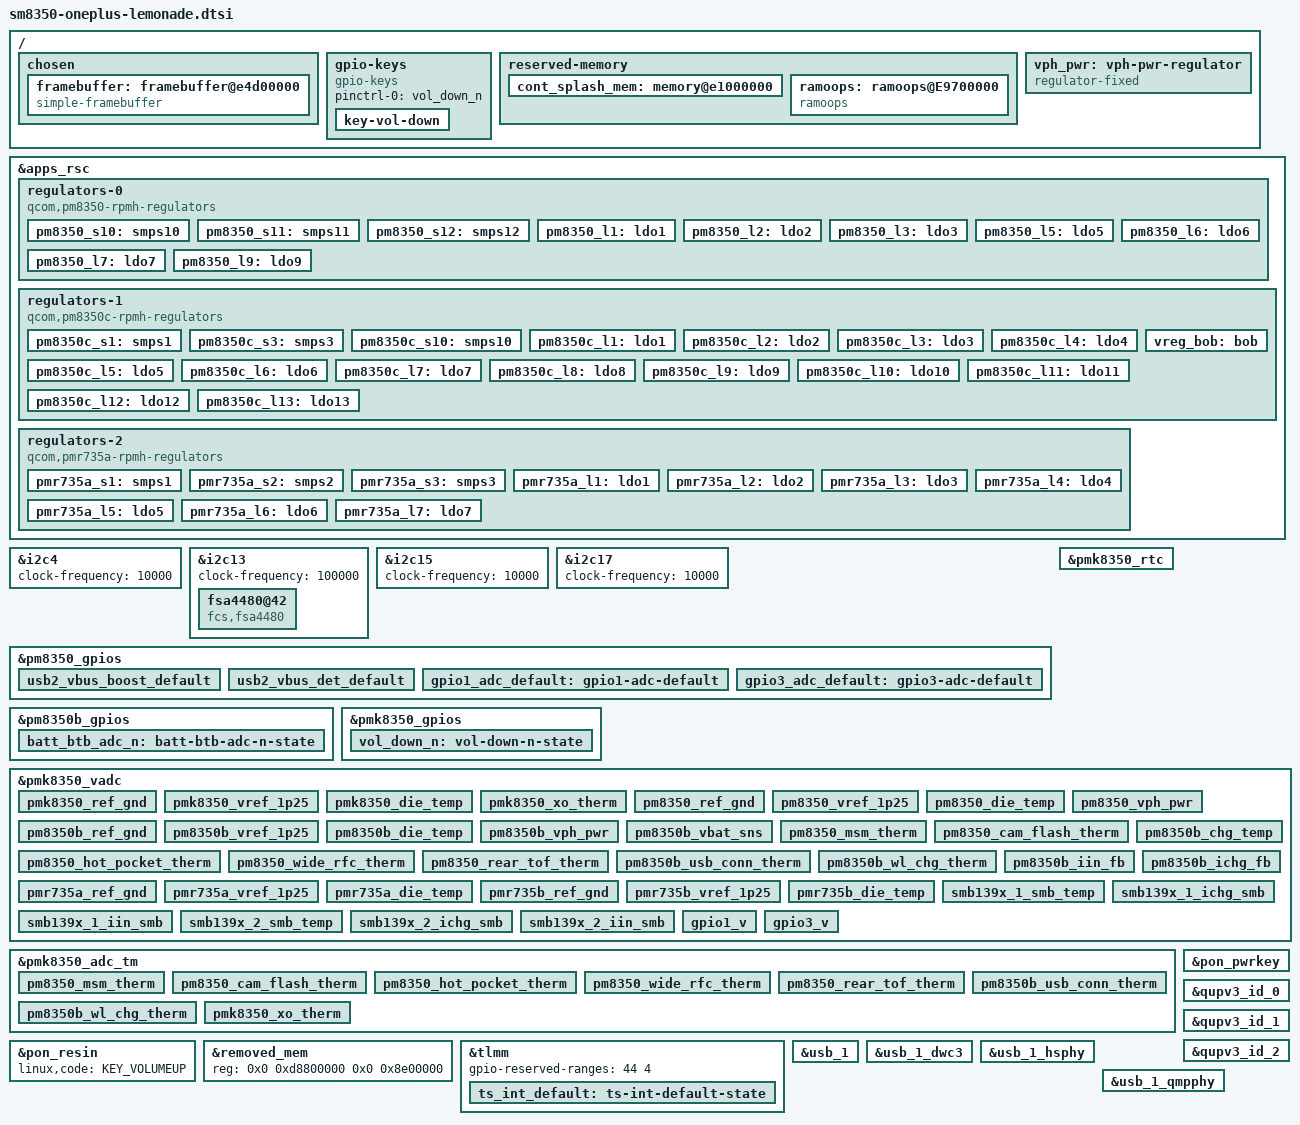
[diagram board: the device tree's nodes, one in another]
// SPDX-License-Identifier: BSD-3-Clause
/*
 *
 * Copyright (c) 2023, Linaro Limited
 */

#include <dt-bindings/iio/qcom,spmi-adc7-pm8350.h>
#include <dt-bindings/iio/qcom,spmi-adc7-pm8350b.h>
#include <dt-bindings/iio/qcom,spmi-adc7-smb139x.h>
#include <dt-bindings/pinctrl/qcom,pmic-gpio.h>
#include <dt-bindings/regulator/qcom,rpmh-regulator.h>
#include "sm8350.dtsi"
#include "pm8350.dtsi"
#include "pm8350b.dtsi"
#include "pm8350c.dtsi"
#include "pmk8350.dtsi"
#include "pmr735a.dtsi"
#include "pmr735b.dtsi"

/ {
	chassis-type = "handset";
	qcom,msm-id = <415 0x10000>, <456 0x10000>;
	qcom,board-id = <0 0>;
	interrupt-parent = <&intc>;

	chosen {
		#address-cells = <2>;
		#size-cells = <2>;
		ranges;

		framebuffer: framebuffer@e4d00000 {
			compatible = "simple-framebuffer";
			reg = <0 0xE4D00000 0 0x2400000>;
			width = <1080>;
			height = <2412>;
			stride = <(1080 * 4)>;
			format = "a8r8g8b8";
			/*
			 * That's (going to be) a lot of clocks, but it's necessary due
			 * to unused clk cleanup & no panel driver yet
			 */
			clocks = <&gcc GCC_DISP_HF_AXI_CLK>,
				 <&gcc GCC_DISP_SF_AXI_CLK>;
		};
	};

	gpio-keys {
		compatible = "gpio-keys";

		pinctrl-names = "default";
		pinctrl-0 = <&vol_down_n>;

		key-vol-down {
			label = "Volume Down";
			linux,code = <KEY_VOLUMEDOWN>;
			gpios = <&pmk8350_gpios 6 GPIO_ACTIVE_LOW>;
			debounce-interval = <15>;
			linux,can-disable;
			wakeup-source;
		};
	};

	// pmic-glink {
	// 	compatible = "qcom,sm8350-pmic-glink", "qcom,pmic-glink";
	// 	#address-cells = <1>;
	// 	#size-cells = <0>;

	// 	connector@0 {
	// 		compatible = "usb-c-connector";
	// 		reg = <0>;
	// 		power-role = "dual";
	// 		data-role = "dual";

	// 		ports {
	// 			#address-cells = <1>;
	// 			#size-cells = <0>;

	// 			port@0 {
	// 				reg = <0>;

	// 				pmic_glink_hs_in: endpoint {
	// 					remote-endpoint = <&usb_1_dwc3_hs>;
	// 				};
	// 			};

	// 			port@1 {
	// 				reg = <1>;

	// 				pmic_glink_ss_in: endpoint {
	// 					remote-endpoint = <&usb_1_dwc3_ss>;
	// 				};
	// 			};
	// 		};
	// 	};
	// };

	reserved-memory {
		cont_splash_mem: memory@e1000000 {
			reg = <0 0xe4d00000 0 0x02400000>;
			no-map;
		};

		ramoops: ramoops@E9700000 {
			compatible = "ramoops";
			reg = <0 0xE9700000 0 0x05B8000>; //5M + 736k
			record-size =  <0x40000>; //256k
			console-size = <0x40000>; //256k
			ftrace-size =  <0x200000>; //2M
			pmsg-size=     <0x200000>; //2M
			devinfo-size=  <0x08000>;  //32k
			dumpinfo-size=  <0x08000>; //32k
			rsv01info-size=  <0x08000>; //32k
			rsv02info-size=  <0x08000>; //32k
			rsv03info-size=  <0x08000>; //32k
			rsv04info-size=  <0x08000>; //32k
			rsv05info-size=  <0x08000>; //32k
			ecc-size=      <0x0>;
		};
	};

	vph_pwr: vph-pwr-regulator {
		compatible = "regulator-fixed";
		regulator-name = "vph_pwr";
		regulator-min-microvolt = <3700000>;
		regulator-max-microvolt = <3700000>;

		regulator-always-on;
		regulator-boot-on;
	};
};

// &adsp {
// 	status = "okay";
// 	firmware-name = "qcom/sm8350/OnePlus/lemonade/adsp.mbn";
// };

&apps_rsc {
	regulators-0 {
		compatible = "qcom,pm8350-rpmh-regulators";
		qcom,pmic-id = "b";

		vdd-s1-supply = <&vph_pwr>;
		vdd-s2-supply = <&vph_pwr>;
		vdd-s3-supply = <&vph_pwr>;
		vdd-s4-supply = <&vph_pwr>;
		vdd-s5-supply = <&vph_pwr>;
		vdd-s6-supply = <&vph_pwr>;
		vdd-s7-supply = <&vph_pwr>;
		vdd-s8-supply = <&vph_pwr>;
		vdd-s9-supply = <&vph_pwr>;
		vdd-s10-supply = <&vph_pwr>;
		vdd-s11-supply = <&vph_pwr>;
		vdd-s12-supply = <&vph_pwr>;

		vdd-l1-l4-supply = <&pm8350_s11>;
		vdd-l2-l7-supply = <&vreg_bob>;
		vdd-l3-l5-supply = <&vreg_bob>;
		vdd-l6-l9-l10-supply = <&pm8350_s11>;

		/*
		 * ARC regulators:
		 * S5 - mx.lvl
		 * S6 - gfx.lvl
		 * S9 - mxc.lvl
		 */

		pm8350_s10: smps10 {
			regulator-name = "pm8350_s10";
			regulator-min-microvolt = <1800000>;
			regulator-max-microvolt = <1800000>;
			regulator-initial-mode = <RPMH_REGULATOR_MODE_HPM>;
		};

		pm8350_s11: smps11 {
			regulator-name = "pm8350_s11";
			regulator-min-microvolt = <752000>;
			regulator-max-microvolt = <1012000>;
			regulator-initial-mode = <RPMH_REGULATOR_MODE_HPM>;
		};

		pm8350_s12: smps12 {
			regulator-name = "pm8350_s12";
			regulator-min-microvolt = <1224000>;
			regulator-max-microvolt = <1360000>;
			regulator-initial-mode = <RPMH_REGULATOR_MODE_HPM>;
		};

		pm8350_l1: ldo1 {
			regulator-name = "pm8350_l1";
			regulator-min-microvolt = <912000>;
			regulator-max-microvolt = <920000>;
			regulator-initial-mode = <RPMH_REGULATOR_MODE_HPM>;
		};

		pm8350_l2: ldo2 {
			regulator-name = "pm8350_l2";
			regulator-min-microvolt = <3072000>;
			regulator-max-microvolt = <3072000>;
			regulator-initial-mode = <RPMH_REGULATOR_MODE_HPM>;
		};

		pm8350_l3: ldo3 {
			regulator-name = "pm8350_l3";
			regulator-min-microvolt = <904000>;
			regulator-max-microvolt = <904000>;
			regulator-initial-mode = <RPMH_REGULATOR_MODE_HPM>;
		};

		/* L4 - lmx.lvl (ARC) */

		pm8350_l5: ldo5 {
			regulator-name = "pm8350_l5";
			regulator-min-microvolt = <880000>;
			regulator-max-microvolt = <888000>;
			regulator-initial-mode = <RPMH_REGULATOR_MODE_HPM>;
			regulator-allow-set-load;
			regulator-allowed-modes = <RPMH_REGULATOR_MODE_LPM
						   RPMH_REGULATOR_MODE_HPM>;
		};

		pm8350_l6: ldo6 {
			regulator-name = "pm8350_l6";
			regulator-min-microvolt = <1200000>;
			regulator-max-microvolt = <1208000>;
			regulator-initial-mode = <RPMH_REGULATOR_MODE_HPM>;
			regulator-allow-set-load;
			regulator-allowed-modes = <RPMH_REGULATOR_MODE_LPM
						   RPMH_REGULATOR_MODE_HPM>;
		};

		pm8350_l7: ldo7 {
			regulator-name = "pm8350_l7";
			regulator-min-microvolt = <2400000>;
			regulator-max-microvolt = <3008000>;
			regulator-initial-mode = <RPMH_REGULATOR_MODE_HPM>;
			regulator-allow-set-load;
			regulator-allowed-modes = <RPMH_REGULATOR_MODE_LPM
						   RPMH_REGULATOR_MODE_HPM>;
		};

		/* L8 - lcx.lvl (ARC) */

		pm8350_l9: ldo9 {
			regulator-name = "pm8350_l9";
			regulator-min-microvolt = <1200000>;
			regulator-max-microvolt = <1200000>;
			regulator-initial-mode = <RPMH_REGULATOR_MODE_HPM>;
			regulator-allow-set-load;
			regulator-allowed-modes = <RPMH_REGULATOR_MODE_LPM
						   RPMH_REGULATOR_MODE_HPM>;
		};
	};

	regulators-1 {
		compatible = "qcom,pm8350c-rpmh-regulators";
		qcom,pmic-id = "c";

		vdd-s1-supply = <&vph_pwr>;
		vdd-s2-supply = <&vph_pwr>;
		vdd-s3-supply = <&vph_pwr>;
		vdd-s4-supply = <&vph_pwr>;
		vdd-s5-supply = <&vph_pwr>;
		vdd-s6-supply = <&vph_pwr>;
		vdd-s7-supply = <&vph_pwr>;
		vdd-s8-supply = <&vph_pwr>;
		vdd-s9-supply = <&vph_pwr>;
		vdd-s10-supply = <&vph_pwr>;

		vdd-l1-l12-supply = <&pm8350c_s1>;
		vdd-l2-l8-supply = <&pm8350c_s1>;
		vdd-l3-l4-l5-l7-l13-supply = <&vreg_bob>;
		vdd-l6-l9-l11-supply = <&vreg_bob>;
		vdd-l10-supply = <&pm8350_s12>;

		vdd-bob-supply = <&vph_pwr>;

		pm8350c_s1: smps1 {
			regulator-name = "pm8350c_s1";
			regulator-min-microvolt = <1800000>;
			regulator-max-microvolt = <1952000>;
			regulator-initial-mode = <RPMH_REGULATOR_MODE_HPM>;
		};

		/* S2 - ebi.lvl (ARC) */

		pm8350c_s3: smps3 {
			regulator-name = "pm8350c_s3";
			regulator-min-microvolt = <300000>;
			regulator-max-microvolt = <704000>;
			regulator-initial-mode = <RPMH_REGULATOR_MODE_HPM>;
		};

		/*
		 * ARC regulators:
		 * S4 - mss.lvl
		 * S6 - cx.lvl
		 * S8 - mmcx.lvl
		 */

		pm8350c_s10: smps10 {
			regulator-name = "pm8350c_s10";
			regulator-min-microvolt = <1048000>;
			regulator-max-microvolt = <1128000>;
			regulator-initial-mode = <RPMH_REGULATOR_MODE_HPM>;
		};

		pm8350c_l1: ldo1 {
			regulator-name = "pm8350c_l1";
			regulator-min-microvolt = <1800000>;
			regulator-max-microvolt = <1800000>;
			regulator-initial-mode = <RPMH_REGULATOR_MODE_HPM>;
		};

		pm8350c_l2: ldo2 {
			regulator-name = "pm8350c_l2";
			regulator-min-microvolt = <1800000>;
			regulator-max-microvolt = <1800000>;
			regulator-initial-mode = <RPMH_REGULATOR_MODE_HPM>;
		};

		pm8350c_l3: ldo3 {
			regulator-name = "pm8350c_l3";
			regulator-min-microvolt = <3000000>;
			regulator-max-microvolt = <3300000>;
			regulator-initial-mode = <RPMH_REGULATOR_MODE_HPM>;
		};

		pm8350c_l4: ldo4 {
			regulator-name = "pm8350c_l4";
			regulator-min-microvolt = <1704000>;
			regulator-max-microvolt = <3000000>;
			regulator-initial-mode = <RPMH_REGULATOR_MODE_HPM>;
		};

		pm8350c_l5: ldo5 {
			regulator-name = "pm8350c_l5";
			regulator-min-microvolt = <1704000>;
			regulator-max-microvolt = <3000000>;
			regulator-initial-mode = <RPMH_REGULATOR_MODE_HPM>;
		};

		pm8350c_l6: ldo6 {
			regulator-name = "pm8350c_l6";
			regulator-min-microvolt = <1800000>;
			regulator-max-microvolt = <2960000>;
			regulator-initial-mode = <RPMH_REGULATOR_MODE_HPM>;
		};

		pm8350c_l7: ldo7 {
			regulator-name = "pm8350c_l7";
			regulator-min-microvolt = <3008000>;
			regulator-max-microvolt = <3008000>;
			regulator-initial-mode = <RPMH_REGULATOR_MODE_HPM>;
		};

		pm8350c_l8: ldo8 {
			regulator-name = "pm8350c_l8";
			regulator-min-microvolt = <1800000>;
			regulator-max-microvolt = <1800000>;
			regulator-initial-mode = <RPMH_REGULATOR_MODE_HPM>;
		};

		pm8350c_l9: ldo9 {
			regulator-name = "pm8350c_l9";
			regulator-min-microvolt = <2800000>;
			regulator-max-microvolt = <3008000>;
			regulator-initial-mode = <RPMH_REGULATOR_MODE_HPM>;
		};

		pm8350c_l10: ldo10 {
			regulator-name = "pm8350c_l10";
			regulator-min-microvolt = <1200000>;
			regulator-max-microvolt = <1200000>;
			regulator-initial-mode = <RPMH_REGULATOR_MODE_HPM>;
		};

		pm8350c_l11: ldo11 {
			regulator-name = "pm8350c_l11";
			regulator-min-microvolt = <2400000>;
			regulator-max-microvolt = <3008000>;
			regulator-initial-mode = <RPMH_REGULATOR_MODE_HPM>;
		};

		pm8350c_l12: ldo12 {
			regulator-name = "pm8350c_l12";
			regulator-min-microvolt = <1800000>;
			regulator-max-microvolt = <2000000>;
			regulator-initial-mode = <RPMH_REGULATOR_MODE_HPM>;
		};

		pm8350c_l13: ldo13 {
			regulator-name = "pm8350c_l13";
			regulator-min-microvolt = <3000000>;
			regulator-max-microvolt = <3200000>;
			regulator-initial-mode = <RPMH_REGULATOR_MODE_HPM>;
		};

		vreg_bob: bob {
			regulator-name = "vreg_bob";
			regulator-min-microvolt = <3400000>;
			regulator-max-microvolt = <3960000>;
			regulator-initial-mode = <RPMH_REGULATOR_MODE_AUTO>;
		};
	};

	/* TODO: Add pm8350b (just one ldo) once the driver part is in */

	regulators-2 {
		compatible = "qcom,pmr735a-rpmh-regulators";
		qcom,pmic-id = "e";

		vdd-s1-supply = <&vph_pwr>;
		vdd-s2-supply = <&vph_pwr>;
		vdd-s3-supply = <&vph_pwr>;

		vdd-l1-l2-supply = <&pmr735a_s2>;
		vdd-l3-supply = <&pmr735a_s1>;
		vdd-l4-supply = <&pm8350c_s1>;
		vdd-l5-l6-supply = <&pm8350c_s1>;
		vdd-l7-bob-supply = <&vreg_bob>;

		pmr735a_s1: smps1 {
			regulator-name = "pmr735a_s1";
			regulator-min-microvolt = <1200000>;
			regulator-max-microvolt = <1280000>;
		};

		pmr735a_s2: smps2 {
			regulator-name = "pmr735a_s2";
			regulator-min-microvolt = <500000>;
			regulator-max-microvolt = <976000>;
		};

		pmr735a_s3: smps3 {
			regulator-name = "pmr735a_s3";
			regulator-min-microvolt = <2208000>;
			regulator-max-microvolt = <2352000>;
		};

		pmr735a_l1: ldo1 {
			regulator-name = "pmr735a_l1";
			regulator-min-microvolt = <912000>;
			regulator-max-microvolt = <912000>;
		};

		pmr735a_l2: ldo2 {
			regulator-name = "pmr735a_l2";
			regulator-min-microvolt = <1200000>;
			regulator-max-microvolt = <1200000>;
		};

		pmr735a_l3: ldo3 {
			regulator-name = "pmr735a_l3";
			regulator-min-microvolt = <1200000>;
			regulator-max-microvolt = <1200000>;
		};

		pmr735a_l4: ldo4 {
			regulator-name = "pmr735a_l4";
			regulator-min-microvolt = <1776000>;
			regulator-max-microvolt = <1872000>;
		};

		pmr735a_l5: ldo5 {
			regulator-name = "pmr735a_l5";
			regulator-min-microvolt = <800000>;
			regulator-max-microvolt = <800000>;
		};

		pmr735a_l6: ldo6 {
			regulator-name = "pmr735a_l6";
			regulator-min-microvolt = <480000>;
			regulator-max-microvolt = <904000>;
		};

		pmr735a_l7: ldo7 {
			regulator-name = "pmr735a_l7";
			regulator-min-microvolt = <2800000>;
			regulator-max-microvolt = <2800000>;
		};
	};
};

// &cdsp {
// 	status = "okay";
// 	firmware-name = "qcom/sm8350/OnePlus/lemonade/cdsp.mbn";
// };

&i2c4 {
	status = "okay";
	/* XXX: Don't forget to increase this.. */
	clock-frequency = <10000>;

	/* Synaptics on-cell S3908 touch controller @ 4B */
};

&i2c13 {
	status = "okay";
	clock-frequency = <100000>;

	fsa4480@42 {
		compatible = "fcs,fsa4480";
		reg = <0x42>;
		mode-switch;
		orientation-switch;
	};

	/* Qualcomm PM8008i/PM8008j (?) @ 8, 9, c, d */
};

&i2c15 {
	status = "okay";
	clock-frequency = <10000>;

	/*
	 * The OnePlus 9 uses a pair of hall sensors for the
	 * tri-state key UP and DOWN detection, one of the
	 * following variants:
	 *
	 * ist8801 hall sensor @ 18, 19
	 * MagnaChip MXM1120 hall sensor @ 0C, 0D
	 */
	
	/* sn-nci NFC controller @ 28 */
};

&i2c17 {
	status = "okay";
	clock-frequency = <10000>;

	/* Awinic aw8697 haptics driver @ 5A */
};

// &ipa {
// 	qcom,gsi-loader = "self";
// 	memory-region = <&pil_ipa_fw_mem>;
// 	firmware-name = "qcom/sm8350/OnePlus/lemonade/ipa_fws.mbn";
// 	status = "okay";
// };

// &mpss {
// 	status = "okay";
// 	firmware-name = "qcom/sm8350/OnePlus/lemonade/modem.mbn";
// };

&pm8350_gpios {
	usb2_vbus_boost_default {
		pins = "gpio8";
		function = "normal";
		output-low;
		power-source = <0x00>;
		phandle = <0x5e1>;
	};

	usb2_vbus_det_default {
		pins = "gpio9";
		function = "normal";
		input-enable;
		bias-disable;
		power-source = <0x00>;
		phandle = <0x5e0>;
	};

	gpio1_adc_default: gpio1-adc-default {
		pins = "gpio1";
		function = "normal";
		bias-high-impedance;
		bias-disable;
		phandle = <0x566>;
	};

	gpio3_adc_default: gpio3-adc-default {
		pins = "gpio3";
		function = "normal";
		bias-high-impedance;
		bias-disable;
		phandle = <0x567>;
	};
};

&pm8350b_gpios {
	batt_btb_adc_n: batt-btb-adc-n-state {
		pins = "gpio2";
		function = "normal";
		bias-pull-up;
		bias-high-impedance;
	};
};

&pmk8350_gpios {
	vol_down_n: vol-down-n-state {
		pins = "gpio6";
		function = "normal";
		power-source = <0>;
		bias-pull-up;
		input-enable;
	};
};

&pmk8350_rtc {
	status = "okay";
};

&pmk8350_vadc {
	pinctrl-0 = <&batt_btb_adc_n &gpio1_adc_default &gpio1_adc_default>;
	pinctrl-names = "default";

	pmk8350_ref_gnd {
		reg = <0x00>;
		label = "pmk8350_ref_gnd";
		qcom,pre-scaling = <0x01 0x01>;
	};

	pmk8350_vref_1p25 {
		reg = <0x01>;
		label = "pmk8350_vref_1p25";
		qcom,pre-scaling = <0x01 0x01>;
	};

	pmk8350_die_temp {
		reg = <0x03>;
		label = "pmk8350_die_temp";
		qcom,pre-scaling = <0x01 0x01>;
	};

	pmk8350_xo_therm {
		reg = <0x44>;
		label = "pmk8350_xo_therm";
		qcom,ratiometric;
		qcom,hw-settle-time = <0xc8>;
		qcom,pre-scaling = <0x01 0x01>;
	};

	pm8350_ref_gnd {
		reg = <0x100>;
		label = "pm8350_ref_gnd";
		qcom,pre-scaling = <0x01 0x01>;
	};

	pm8350_vref_1p25 {
		reg = <0x101>;
		label = "pm8350_vref_1p25";
		qcom,pre-scaling = <0x01 0x01>;
	};

	pm8350_die_temp {
		reg = <0x103>;
		label = "pm8350_die_temp";
		qcom,pre-scaling = <0x01 0x01>;
	};

	pm8350_vph_pwr {
		reg = <0x18e>;
		label = "pm8350_vph_pwr";
		qcom,pre-scaling = <0x01 0x03>;
	};

	pm8350b_ref_gnd {
		reg = <0x300>;
		label = "pm8350b_ref_gnd";
		qcom,pre-scaling = <0x01 0x01>;
	};

	pm8350b_vref_1p25 {
		reg = <0x301>;
		label = "pm8350b_vref_1p25";
		qcom,pre-scaling = <0x01 0x01>;
	};

	pm8350b_die_temp {
		reg = <0x303>;
		label = "pm8350b_die_temp";
		qcom,pre-scaling = <0x01 0x01>;
	};

	pm8350b_vph_pwr {
		reg = <0x38e>;
		label = "pm8350b_vph_pwr";
		qcom,pre-scaling = <0x01 0x03>;
	};

	pm8350b_vbat_sns {
		reg = <0x38f>;
		label = "pm8350b_vbat_sns";
		qcom,pre-scaling = <0x01 0x03>;
	};

	pm8350_msm_therm {
		reg = <PM8350_ADC7_AMUX_THM1_100K_PU(1)>;
		label = "pm8350_msm_therm";
		qcom,ratiometric;
		qcom,hw-settle-time = <200>;
		qcom,pre-scaling = <1 1>;
	};

	pm8350_cam_flash_therm {
		reg = <PM8350_ADC7_AMUX_THM2_100K_PU(1)>;
		label = "pm8350_cam_flash_therm";
		qcom,ratiometric;
		qcom,hw-settle-time = <200>;
		qcom,pre-scaling = <1 1>;
	};

	pm8350_hot_pocket_therm {
		reg = <PM8350_ADC7_AMUX_THM3_100K_PU(1)>;
		label = "pm8350_hot_pocket_therm";
		qcom,ratiometric;
		qcom,hw-settle-time = <200>;
		qcom,pre-scaling = <1 1>;
	};

	pm8350_wide_rfc_therm {
		reg = <PM8350_ADC7_AMUX_THM4_100K_PU(1)>;
		label = "pm8350_wide_rfc_therm";
		qcom,ratiometric;
		qcom,hw-settle-time = <200>;
		qcom,pre-scaling = <1 1>;
	};

	pm8350_rear_tof_therm {
		reg = <PM8350_ADC7_AMUX_THM5_100K_PU(1)>;
		label = "pm8350_rear_tof_therm";
		qcom,ratiometric;
		qcom,hw-settle-time = <200>;
		qcom,pre-scaling = <1 1>;
	};

	pm8350b_usb_conn_therm {
		reg = <PM8350B_ADC7_AMUX_THM4_100K_PU>;
		label = "pm8350b_usb_conn_therm";
		qcom,ratiometric;
		qcom,hw-settle-time = <200>;
		qcom,pre-scaling = <1 1>;
	};

	pm8350b_wl_chg_therm {
		reg = <PM8350B_ADC7_GPIO2_100K_PU>;
		label = "pm8350b_wl_chg_therm";
		qcom,ratiometric;
		qcom,hw-settle-time = <200>;
		qcom,pre-scaling = <1 1>;
	};

	pm8350b_chg_temp {
		reg = <PM8350B_ADC7_CHG_TEMP>;
		label = "pm8350b_chg_temp";
		qcom,pre-scaling = <1 1>;
	};

	pm8350b_iin_fb {
		reg = <PM8350B_ADC7_IIN_FB>;
		label = "pm8350b_iin_fb";
		qcom,pre-scaling = <32 100>;
	};

	pm8350b_ichg_fb {
		reg = <PM8350B_ADC7_ICHG_FB>;
		label = "pm8350b_ichg_fb";
		qcom,pre-scaling = <1000 305185>;
	};

	pmr735a_ref_gnd {
		reg = <0x400>;
		label = "pmr735a_ref_gnd";
		qcom,pre-scaling = <0x01 0x01>;
	};

	pmr735a_vref_1p25 {
		reg = <0x401>;
		label = "pmr735a_vref_1p25";
		qcom,pre-scaling = <0x01 0x01>;
	};

	pmr735a_die_temp {
		reg = <0x403>;
		label = "pmr735a_die_temp";
		qcom,pre-scaling = <0x01 0x01>;
	};

	pmr735b_ref_gnd {
		reg = <0x500>;
		label = "pmr735b_ref_gnd";
		qcom,pre-scaling = <0x01 0x01>;
	};

	pmr735b_vref_1p25 {
		reg = <0x501>;
		label = "pmr735b_vref_1p25";
		qcom,pre-scaling = <0x01 0x01>;
	};

	pmr735b_die_temp {
		reg = <0x503>;
		label = "pmr735b_die_temp";
		qcom,pre-scaling = <0x01 0x01>;
	};

	smb139x_1_smb_temp {
		reg = <SMB139x_1_ADC7_SMB_TEMP>;
		label = "smb139x_1_smb_temp";
		qcom,pre-scaling = <1 1>;
	};

	smb139x_1_ichg_smb {
		reg = <SMB139x_1_ADC7_ICHG_SMB>;
		label = "smb139x_1_ichg_smb";
		qcom,pre-scaling = <16 100>;
	};

	smb139x_1_iin_smb {
		reg = <SMB139x_1_ADC7_IIN_SMB>;
		label = "smb139x_1_iin_smb";
		qcom,pre-scaling = <32 100>;
	};

	smb139x_2_smb_temp {
		reg = <SMB139x_2_ADC7_SMB_TEMP>;
		label = "smb139x_2_smb_temp";
		qcom,pre-scaling = <1 1>;
	};

	smb139x_2_ichg_smb {
		reg = <SMB139x_2_ADC7_ICHG_SMB>;
		label = "smb139x_2_ichg_smb";
		qcom,pre-scaling = <16 100>;
	};

	smb139x_2_iin_smb {
		reg = <SMB139x_2_ADC7_IIN_SMB>;
		label = "smb139x_2_iin_smb";
		qcom,pre-scaling = <32 100>;
	};

	gpio1_v {
		reg = <0x128>;
		label = "gpio1_v";
		qcom,ratiometric;
		qcom,hw-settle-time = <0x2bc>;
		qcom,pre-scaling = <0x01 0x01>;
	};

	gpio3_v {
		reg = <0x12b>;
		label = "gpio3_v";
		qcom,ratiometric;
		qcom,hw-settle-time = <0x2bc>;
		qcom,pre-scaling = <0x01 0x01>;
	};
};

&pmk8350_adc_tm {
	pm8350_msm_therm {
		reg = <0x144>;
		qcom,ratiometric;
		qcom,hw-settle-time = <0xc8>;
	};

	pm8350_cam_flash_therm {
		reg = <0x145>;
		qcom,ratiometric;
		qcom,hw-settle-time = <0xc8>;
	};

	pm8350_hot_pocket_therm {
		reg = <0x146>;
		qcom,ratiometric;
		qcom,hw-settle-time = <0xc8>;
	};

	pm8350_wide_rfc_therm {
		reg = <0x147>;
		qcom,ratiometric;
		qcom,hw-settle-time = <0xc8>;
	};

	pm8350_rear_tof_therm {
		reg = <0x148>;
		qcom,ratiometric;
		qcom,hw-settle-time = <0xc8>;
	};

	pm8350b_usb_conn_therm {
		reg = <0x347>;
		qcom,ratiometric;
		qcom,hw-settle-time = <0xc8>;
	};

	pm8350b_wl_chg_therm {
		reg = <0x34b>;
		qcom,ratiometric;
		qcom,hw-settle-time = <0xc8>;
	};

	pmk8350_xo_therm {
		reg = <0x44>;
		qcom,ratiometric;
		qcom,hw-settle-time = <0xc8>;
	};
};

&pon_pwrkey {
	status = "okay";
};

&pon_resin {
	status = "okay";
	linux,code = <KEY_VOLUMEUP>;
};

&qupv3_id_0 {
	status = "okay";
};

&qupv3_id_1 {
	status = "okay";
};

&qupv3_id_2 {
	status = "okay";
};

&removed_mem {
	reg = <0x0 0xd8800000 0x0 0x8e00000>;
};

// &slpi {
// 	status = "okay";
// 	firmware-name = "qcom/sm8350/OnePlus/lemonade/slpi.mbn";
// };

&tlmm {
	gpio-reserved-ranges = <44 4>;

	ts_int_default: ts-int-default-state {
		pins = "gpio23";
		function = "gpio";
		drive-strength = <2>;
		bias-disable;
	};
};

// &ufs_mem_hc {
// 	status = "okay";

// 	reset-gpios = <&tlmm 203 GPIO_ACTIVE_LOW>;

// 	vcc-supply = <&pm8350_l7>;
// 	vcc-max-microamp = <800000>;
// 	vccq-supply = <&pm8350_l9>;
// 	vccq-max-microamp = <900000>;
// };

// &ufs_mem_phy {
// 	status = "okay";

// 	vdda-phy-supply = <&pm8350_l5>;
// 	vdda-pll-supply = <&pm8350_l6>;
// };

&usb_1 {
	status = "okay";
};

&usb_1_dwc3 {
	dr_mode = "peripheral";
	/* Disabled on downstream, probably intefers with VOOC */
	snps,usb2-gadget-lpm-disable;
	//usb-role-switch;
};

// &usb_1_dwc3_hs {
// 	remote-endpoint = <&pmic_glink_hs_in>;
// };

// &usb_1_dwc3_ss {
// 	remote-endpoint = <&pmic_glink_ss_in>;
// };

&usb_1_hsphy {
	status = "okay";

	vdda-pll-supply = <&pm8350_l5>;
	vdda18-supply = <&pm8350c_l1>;
	vdda33-supply = <&pm8350_l2>;
};

&usb_1_qmpphy {
	status = "okay";

	vdda-phy-supply = <&pm8350_l6>;
	vdda-pll-supply = <&pm8350_l1>;
};
